# AT91SAM9G20 register map
Vendor: Atmel; File version: 20130207
CPU: 
Registers are 32-bit, read-write, reset 0x0 unless marked. A register's access mark holds for its fields unless they carry their own. Offsets are from the block's base; [hi:lo] are bit positions; {n}, {i} and the like mark numbered series; 'fields as' and 'values as' point back to an identical list.

## PIOA — Parallel Input/Output Controller A
Base 0xFFFFF400; register names take the prefix PIOA_
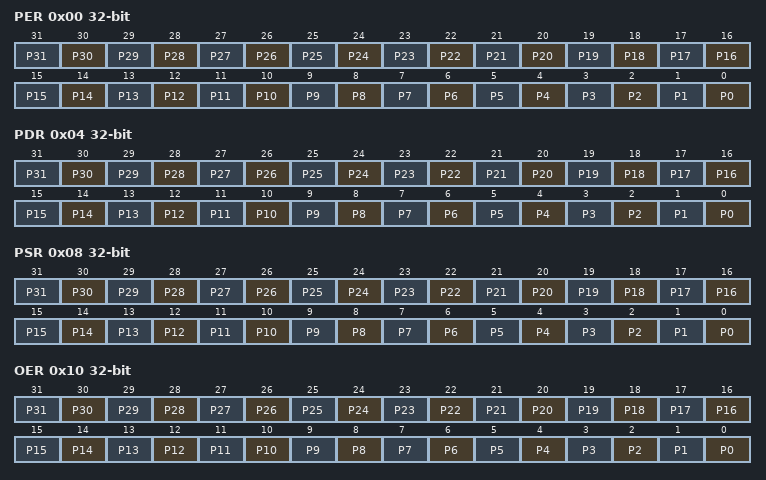
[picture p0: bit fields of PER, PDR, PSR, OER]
0x00 PER wo reset not defined — PIO Enable Register
  [n] P{n} (n=0..31) — PIO Enable
0x04 PDR wo reset not defined — PIO Disable Register
  [n] P{n} (n=0..31) — PIO Disable
0x08 PSR ro reset not defined — PIO Status Register
  [n] P{n} (n=0..31) — PIO Status
0x10 OER wo reset not defined — Output Enable Register
  [n] P{n} (n=0..31) — Output Enable
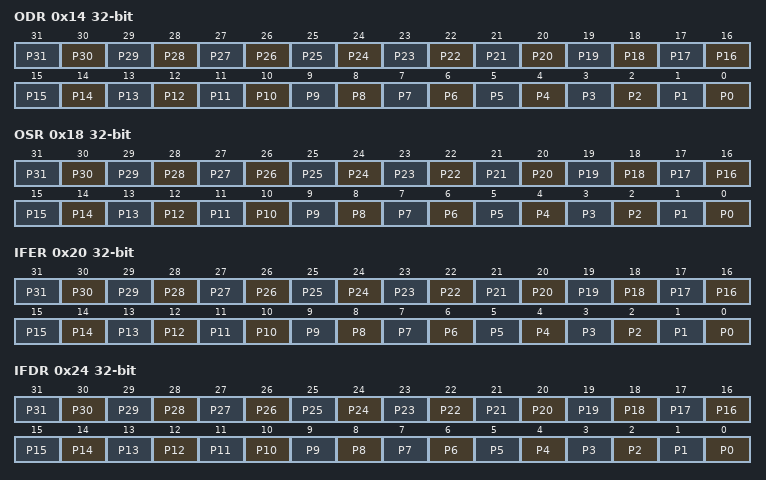
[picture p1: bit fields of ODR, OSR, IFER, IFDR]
0x14 ODR wo reset not defined — Output Disable Register
  [n] P{n} (n=0..31) — Output Disable
0x18 OSR ro — Output Status Register
  [n] P{n} (n=0..31) — Output Status
0x20 IFER wo reset not defined — Glitch Input Filter Enable Register
  [n] P{n} (n=0..31) — Input Filter Enable
0x24 IFDR wo reset not defined — Glitch Input Filter Disable Register
  [n] P{n} (n=0..31) — Input Filter Disable
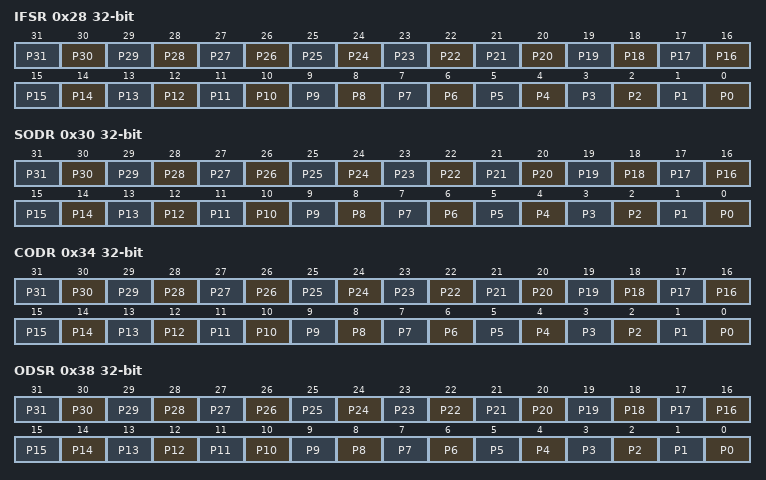
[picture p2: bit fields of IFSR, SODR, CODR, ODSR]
0x28 IFSR ro — Glitch Input Filter Status Register
  [n] P{n} (n=0..31) — Input Filer Status
0x30 SODR wo reset not defined — Set Output Data Register
  [n] P{n} (n=0..31) — Set Output Data
0x34 CODR wo reset not defined — Clear Output Data Register
  [n] P{n} (n=0..31) — Set Output Data
0x38 ODSR reset not defined — Output Data Status Register
  [n] P{n} (n=0..31) — Output Data Status
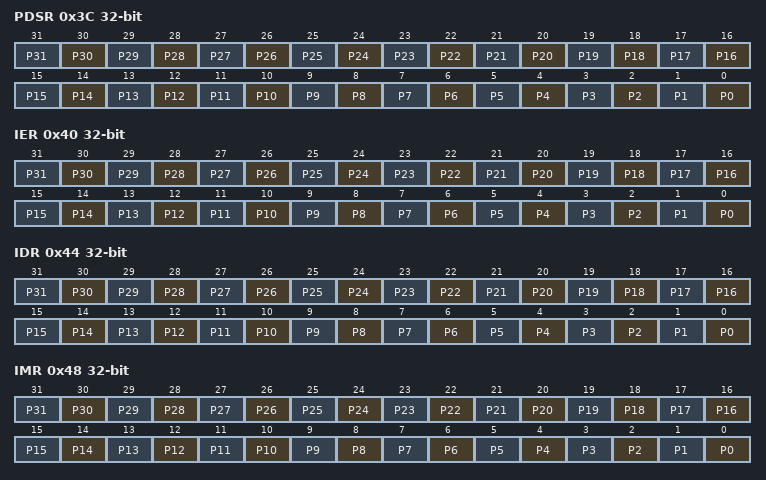
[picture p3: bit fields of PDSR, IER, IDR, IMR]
0x3C PDSR ro reset not defined — Pin Data Status Register
  [n] P{n} (n=0..31) — Output Data Status
0x40 IER wo reset not defined — Interrupt Enable Register
  [n] P{n} (n=0..31) — Input Change Interrupt Enable
0x44 IDR wo reset not defined — Interrupt Disable Register
  [n] P{n} (n=0..31) — Input Change Interrupt Disable
0x48 IMR ro — Interrupt Mask Register
  [n] P{n} (n=0..31) — Input Change Interrupt Mask
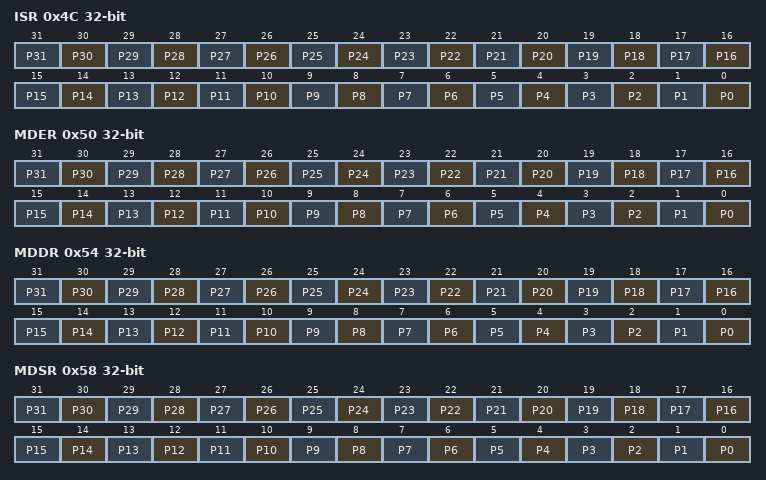
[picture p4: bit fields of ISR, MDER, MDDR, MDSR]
0x4C ISR ro — Interrupt Status Register
  [n] P{n} (n=0..31) — Input Change Interrupt Status
0x50 MDER wo reset not defined — Multi-driver Enable Register
  [n] P{n} (n=0..31) — Multi Drive Enable.
0x54 MDDR wo reset not defined — Multi-driver Disable Register
  [n] P{n} (n=0..31) — Multi Drive Disable.
0x58 MDSR ro — Multi-driver Status Register
  [n] P{n} (n=0..31) — Multi Drive Status.
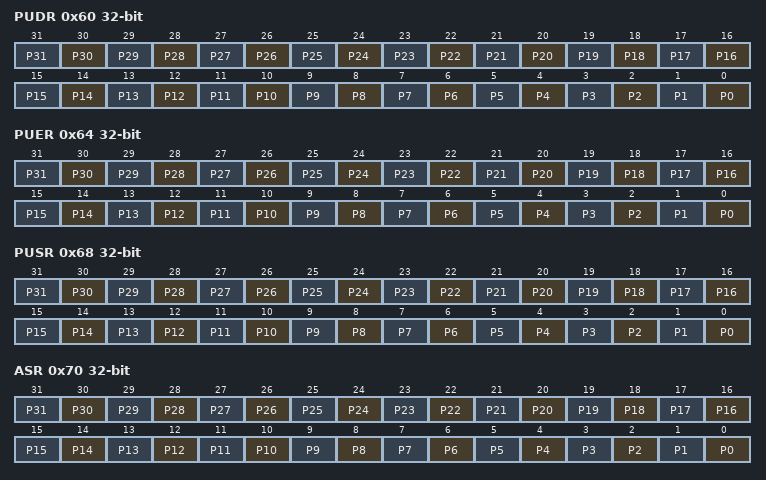
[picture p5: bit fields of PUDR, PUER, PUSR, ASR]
0x60 PUDR wo reset not defined — Pull-up Disable Register
  [n] P{n} (n=0..31) — Pull Up Disable.
0x64 PUER wo reset not defined — Pull-up Enable Register
  [n] P{n} (n=0..31) — Pull Up Enable.
0x68 PUSR ro — Pad Pull-up Status Register
  [n] P{n} (n=0..31) — Pull Up Status.
0x70 ASR wo reset not defined — Peripheral A Select Register
  [n] P{n} (n=0..31) — Peripheral A Select.
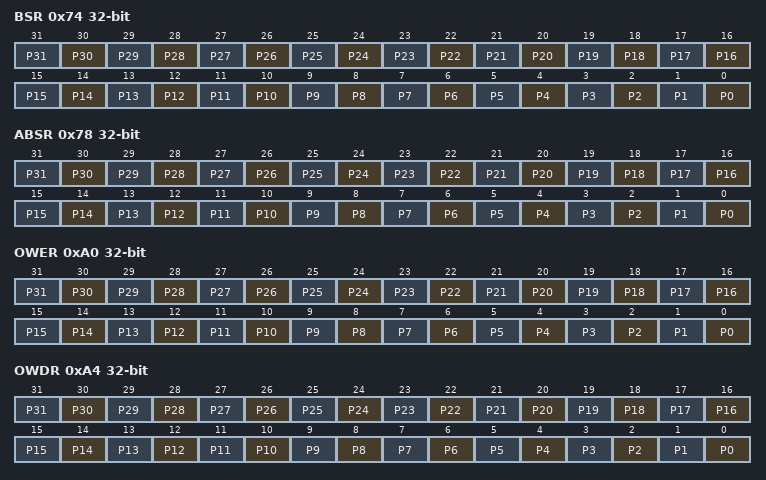
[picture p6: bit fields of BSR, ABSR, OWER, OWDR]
0x74 BSR wo reset not defined — Peripheral B Select Register
  [n] P{n} (n=0..31) — Peripheral B Select.
0x78 ABSR ro — AB Status Register
  [n] P{n} (n=0..31) — Peripheral A B Status.
0xA0 OWER wo reset not defined — Output Write Enable
  [n] P{n} (n=0..31) — Output Write Enable.
0xA4 OWDR wo reset not defined — Output Write Disable
  [n] P{n} (n=0..31) — Output Write Disable.
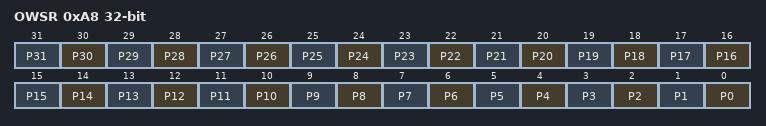
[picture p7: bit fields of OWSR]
0xA8 OWSR ro — Output Write Status Register
  [n] P{n} (n=0..31) — Output Write Status.

## PIOB — Parallel Input/Output Controller B
Base 0xFFFFF600; register names take the prefix PIOB_
Registers as PIOA.

## PIOC — Parallel Input/Output Controller C
Base 0xFFFFF800; register names take the prefix PIOC_
Registers as PIOA.

## RSTC — Reset Controller
Base 0xFFFFFD00; register names take the prefix RSTC_
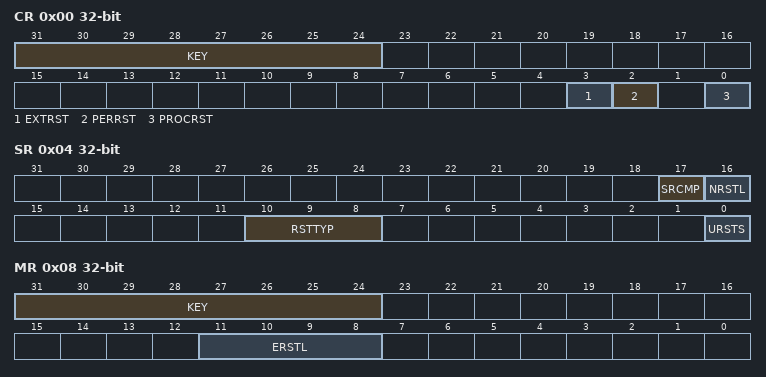
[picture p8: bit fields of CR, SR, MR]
0x00 CR wo reset not defined — Control Register
  [31:24] KEY — Password
  [3] EXTRST — External Reset
  [2] PERRST — Peripheral Reset
  [0] PROCRST — Processor Reset
0x04 SR ro — Status Register
  [17] SRCMP — Software Reset Command in Progress
  [16] NRSTL — NRST Pin Level
  [10:8] RSTTYP — Reset Type
  [0] URSTS — User Reset Status
0x08 MR — Mode Register
  [31:24] KEY — Password
  [11:8] ERSTL — External Reset Length

## SHDWC — Shutdown Controller
Base 0xFFFFFD10; register names take the prefix SHDWC_
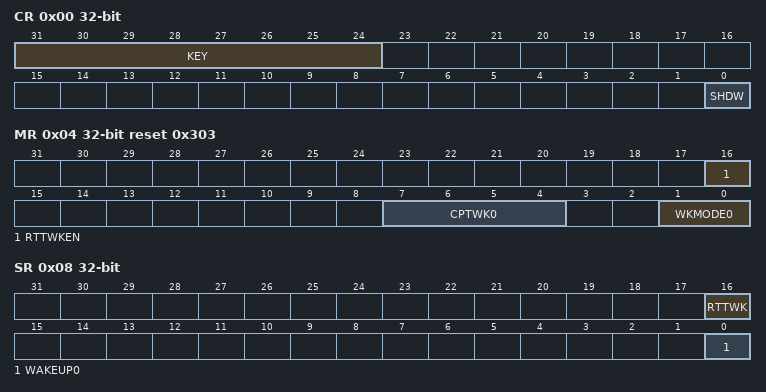
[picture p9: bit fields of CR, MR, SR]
0x00 CR wo reset not defined — Shutdown Control Register
  [31:24] KEY — Password
  [0] SHDW — Shutdown Command
0x04 MR reset 0x303 — Shutdown Mode Register
  [16] RTTWKEN — Real-time Timer Wake-up Enable
  [7:4] CPTWK0 — Counter on Wake-up 0
  [1:0] WKMODE0 — Wake-up Mode 0
0x08 SR ro — Shutdown Status Register
  [16] RTTWK — Real-time Timer Wake-up
  [0] WAKEUP0 — Wake-up 0 Status

## RTT — Real-time Timer
Base 0xFFFFFD20; register names take the prefix RTT_
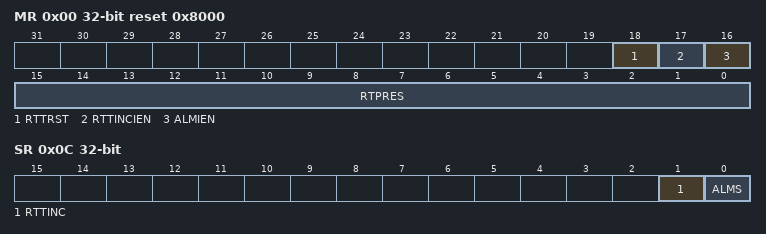
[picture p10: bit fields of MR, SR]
0x00 MR reset 0x8000 — Mode Register
  [18] RTTRST — Real-time Timer Restart
  [17] RTTINCIEN — Real-time Timer Increment Interrupt Enable
  [16] ALMIEN — Alarm Interrupt Enable
  [15:0] RTPRES — Real-time Timer Prescaler Value
0x04 AR reset 0xFFFFFFFF — Alarm Register
  [31:0] ALMV — Alarm Value
0x08 VR ro — Value Register
  [31:0] CRTV — Current Real-time Value
0x0C SR ro — Status Register
  [1] RTTINC — Real-time Timer Increment
  [0] ALMS — Real-time Alarm Status

## PIT — Periodic Interval Timer
Base 0xFFFFFD30; register names take the prefix PIT_
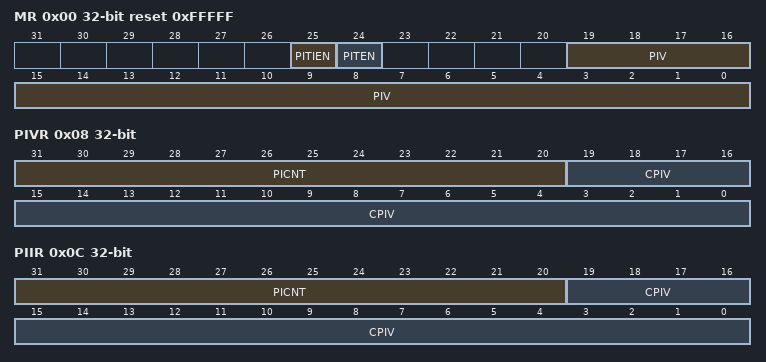
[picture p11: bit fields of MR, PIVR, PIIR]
0x00 MR reset 0xFFFFF — Mode Register
  [25] PITIEN — Periodic Interval Timer Interrupt Enable
  [24] PITEN — Period Interval Timer Enabled
  [19:0] PIV — Periodic Interval Value
0x04 SR ro — Status Register
  [0] PITS — Periodic Interval Timer Status
0x08 PIVR ro — Periodic Interval Value Register
  [31:20] PICNT — Periodic Interval Counter
  [19:0] CPIV — Current Periodic Interval Value
0x0C PIIR ro — Periodic Interval Image Register
  fields as PIVR

## WDT — Watchdog Timer
Base 0xFFFFFD40; register names take the prefix WDT_
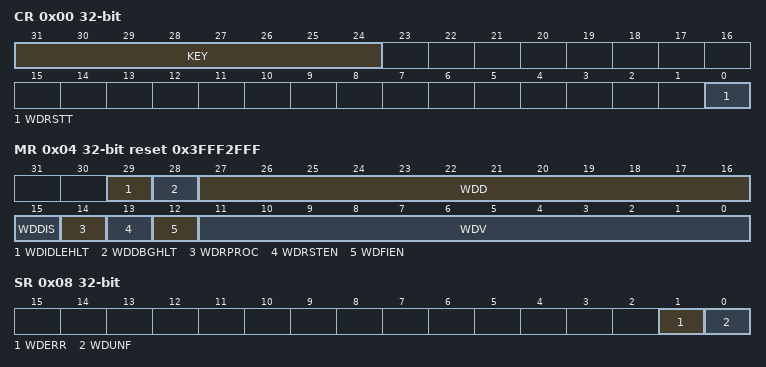
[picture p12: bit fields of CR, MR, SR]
0x00 CR wo reset not defined — Control Register
  [31:24] KEY — Password
  [0] WDRSTT — Watchdog Restart
0x04 MR reset 0x3FFF2FFF — Mode Register
  [29] WDIDLEHLT — Watchdog Idle Halt
  [28] WDDBGHLT — Watchdog Debug Halt
  [27:16] WDD — Watchdog Delta Value
  [15] WDDIS — Watchdog Disable
  [14] WDRPROC — Watchdog Reset Processor
  [13] WDRSTEN — Watchdog Reset Enable
  [12] WDFIEN — Watchdog Fault Interrupt Enable
  [11:0] WDV — Watchdog Counter Value
0x08 SR ro — Status Register
  [1] WDERR — Watchdog Error
  [0] WDUNF — Watchdog Underflow

## GPBR — General Purpose Backup Register
Base 0xFFFFFD50; register names take the prefix GPBR_
{0x0+4i} GPBR[{i}] reset not defined (i=0..3) — General Purpose Backup Register
  [31:0] GPBR_VALUE — Value of GPBR x
